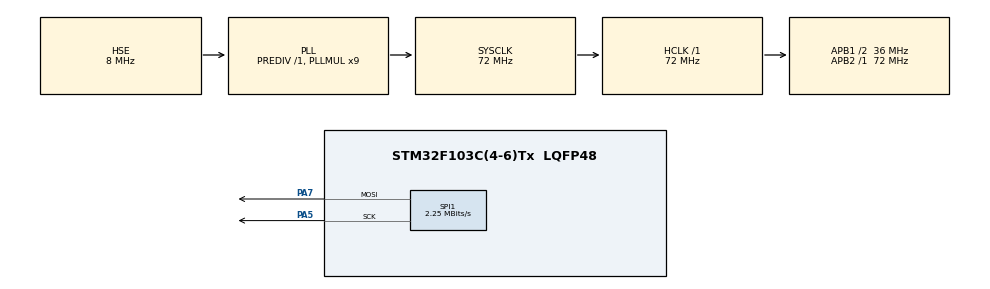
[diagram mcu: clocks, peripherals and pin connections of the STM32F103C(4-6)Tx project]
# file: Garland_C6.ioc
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ADC1.Channel-1\#ChannelRegularConversion=ADC_CHANNEL_TEMPSENSOR
ADC1.NbrOfConversionFlag=1
ADC1.Rank-1\#ChannelRegularConversion=1
ADC1.SamplingTime-1\#ChannelRegularConversion=ADC_SAMPLETIME_1CYCLE_5
ADC1.master=1
Dma.Request0=SPI1_TX
Dma.SPI1_TX.0.Direction=DMA_MEMORY_TO_PERIPH
Dma.SPI1_TX.0.Instance=DMA1_Channel3
Dma.SPI1_TX.0.MemDataAlignment=DMA_MDATAALIGN_BYTE
Dma.SPI1_TX.0.MemInc=DMA_MINC_ENABLE
Dma.SPI1_TX.0.Mode=DMA_NORMAL
Dma.SPI1_TX.0.PeriphDataAlignment=DMA_PDATAALIGN_BYTE
Dma.SPI1_TX.0.PeriphInc=DMA_PINC_DISABLE
Dma.SPI1_TX.0.Priority=DMA_PRIORITY_LOW
Mcu.Family=STM32F1
Mcu.Name=STM32F103C(4-6)Tx
Mcu.Package=LQFP48
NVIC.ADC1_2_IRQn=true\:0\:0\:false\:false\:true\:true\:true\:true
NVIC.DMA1_Channel3_IRQn=true\:0\:0\:false\:false\:true\:false\:true\:true
NVIC.PriorityGroup=NVIC_PRIORITYGROUP_4
NVIC.TIM1_BRK_IRQn=true\:0\:0\:false\:false\:true\:true\:true\:true
NVIC.TIM1_CC_IRQn=true\:0\:0\:false\:false\:true\:true\:true\:true
NVIC.TIM1_TRG_COM_IRQn=true\:0\:0\:false\:false\:true\:true\:true\:true
NVIC.TIM1_UP_IRQn=true\:0\:0\:false\:false\:true\:true\:true\:true
PA13.Mode=Serial_Wire
PA13.Signal=SYS_JTMS-SWDIO
PA14.Mode=Serial_Wire
PA14.Signal=SYS_JTCK-SWCLK
PA5.Mode=TX_Only_Simplex_Unidirect_Master
PA5.Signal=SPI1_SCK
PA7.Mode=TX_Only_Simplex_Unidirect_Master
PA7.Signal=SPI1_MOSI
PD0-OSC_IN.Mode=HSE-External-Oscillator
PD0-OSC_IN.Signal=RCC_OSC_IN
PD1-OSC_OUT.Mode=HSE-External-Oscillator
PD1-OSC_OUT.Signal=RCC_OSC_OUT
ProjectManager.HeapSize=0x0
ProjectManager.StackSize=0x400
ProjectManager.TargetToolchain=STM32CubeIDE
RCC.ADCPresc=RCC_ADCPCLK2_DIV6
RCC.AHBFreq_Value=72000000
RCC.APB1CLKDivider=RCC_HCLK_DIV2
RCC.APB1Freq_Value=36000000
RCC.APB1TimFreq_Value=72000000
RCC.APB2Freq_Value=72000000
RCC.APB2TimFreq_Value=72000000
RCC.FLatency=FLASH_LATENCY_2
RCC.HCLKFreq_Value=72000000
RCC.PLLMUL=RCC_PLL_MUL9
RCC.PLLSourceVirtual=RCC_PLLSOURCE_HSE
RCC.SYSCLKFreq_VALUE=72000000
RCC.SYSCLKSource=RCC_SYSCLKSOURCE_PLLCLK
RCC.USBFreq_Value=72000000
SPI1.BaudRatePrescaler=SPI_BAUDRATEPRESCALER_32
SPI1.CLKPhase=SPI_PHASE_2EDGE
SPI1.CLKPolarity=SPI_POLARITY_LOW
SPI1.CRCCalculation=SPI_CRCCALCULATION_DISABLE
SPI1.CalculateBaudRate=2.25 MBits/s
SPI1.DataSize=SPI_DATASIZE_8BIT
SPI1.Direction=SPI_DIRECTION_2LINES
SPI1.FirstBit=SPI_FIRSTBIT_MSB
SPI1.Mode=SPI_MODE_MASTER
SPI1.NSS=SPI_NSS_SOFT
SPI1.TIMode=SPI_TIMODE_DISABLE
SPI1.VirtualType=VM_MASTER
TIM1.AutoReloadPreload=TIM_AUTORELOAD_PRELOAD_DISABLE
TIM1.ClockDivision=TIM_CLOCKDIVISION_DIV1
TIM1.CounterMode=TIM_COUNTERMODE_UP
TIM1.Period=20000
TIM1.Prescaler=71
TIM1.TIM_MasterOutputTrigger=TIM_TRGO_RESET
TIM1.TIM_MasterSlaveMode=TIM_MASTERSLAVEMODE_DISABLE
VP_ADC1_TempSens_Input.Mode=IN-TempSens
VP_CRC_VS_CRC.Mode=CRC_Activate
VP_TIM1_VS_ClockSourceINT.Mode=Internal
board=custom

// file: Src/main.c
/* USER CODE BEGIN Header */
/**
  ******************************************************************************
  * @file           : main.c
  * @brief          : Main program body
  ******************************************************************************
  * @attention
  *
  * Copyright (c) 2024 STMicroelectronics.
  * All rights reserved.
  *
  * This software is licensed under terms that can be found in the LICENSE file
  * in the root directory of this software component.
  * If no LICENSE file comes with this software, it is provided AS-IS.
  *
  ******************************************************************************
  */
/* USER CODE END Header */
#include "main.h"

/* USER CODE BEGIN Includes */
#include "random.h"
#include "ws2812.h"
#include "stdlib.h"
#include <string.h>
/* USER CODE END Includes */

/* USER CODE BEGIN PD */
#define TIMER_PERIOD_MS			20	// Период вызова функции обновления состояния
#define TIME_MIN_TICK			(TIME_MIN_MSEC / TIMER_PERIOD_MS)
#define TIME_MAX_TICK			(TIME_MAX_MSEC / TIMER_PERIOD_MS)
/* USER CODE END PD */

ADC_HandleTypeDef hadc1;

CRC_HandleTypeDef hcrc;

SPI_HandleTypeDef hspi1;
DMA_HandleTypeDef hdma_spi1_tx;

TIM_HandleTypeDef htim1;

/* USER CODE BEGIN PV */
volatile uint8_t timFlag = 0;
volatile uint8_t dmaFlag = 1;
uint32_t rgbArr[LED_NUM]; // кольцевой массив
const uint32_t rgbConst[8]={0x000000, 0x00007F, 0x007F00, 0x007F7F, 0x7F0000, 0x7F007F, 0x7F7F00, 0x7F7F7F};
volatile uint32_t timerCounter;
/* USER CODE END PV */

void SystemClock_Config(void);
static void MX_GPIO_Init(void);
static void MX_DMA_Init(void);
static void MX_SPI1_Init(void);
static void MX_ADC1_Init(void);
static void MX_CRC_Init(void);
static void MX_TIM1_Init(void);

/* USER CODE BEGIN 0 */
void HAL_ADC_ConvCpltCallback(ADC_HandleTypeDef* hadc)
{
	static uint32_t count = 0;
	count++;
	uint32_t adc = HAL_ADC_GetValue(hadc);
	uint8_t ans = Random_AddBit(adc);
	if (ans != 0)
		HAL_ADC_Start_IT(&hadc1);
	else
		__NOP();
}

void HAL_TIM_PeriodElapsedCallback(TIM_HandleTypeDef *htim)
{
	timFlag = 1;
	timerCounter++;
}

void HAL_SPI_TxCpltCallback(SPI_HandleTypeDef *hspi)
{
	dmaFlag = 1 ;
}

// type  0 - linear; 1 - V образный
// при 0 - возврат 32 бит, при 1 - только 8
uint32_t GetRandom(uint8_t type)
{
	uint32_t rnd;
	static uint8_t isFirst = 1;
	if (isFirst)
	{
		isFirst = 0;
		rnd = Random_GetRnd();
		HAL_ADC_Start_IT(&hadc1);
		while (!rnd)
		{
			rnd = Random_GetRnd();
		};
		srand(rnd);
	}

	rnd = rand();
	if (type == 0)
		return rnd;

	// V
	return Random_GetV(rnd);
}

// Бегущие огни
void Prog_0()
{
	static uint32_t timer = 0;
	static uint32_t curr = 0;
	static uint32_t dest = 0;

	uint8_t* currP = (uint8_t*)&curr;
	uint8_t* destP = (uint8_t*)&dest;
	// Задаем цвет нулевому диоду
	if (!timer)
	{
		timer = 0xFF;
		curr = dest;
		do
		{
			dest = rgbConst[GetRandom(0)&7];
		}while (curr == dest);

	}
	else
	{
		timer--;
		for(int i=0; i<3; i++)
			if (destP[i])
			{
				if (currP[i] < 0xFF)
					currP[i]++;
			}
			else
			{
				if (currP[i] > 0)
					currP[i]--;
			}
	}

	// Передаем в массив
	for (int i = LED_NUM-1; i>0; i--)
		rgbArr[i] = rgbArr[i-1];

	rgbArr[0] = curr;

	for(int i=0; i<LED_NUM; i++)
		ws2813_AddRGB(rgbArr[i], i);
}

// Случайная вспышка
void Prog_1()
{
	for (int i=0; i<10; i++)
	{
		uint32_t rnd = rgbConst[GetRandom(0)&7];
		uint16_t pos = GetRandom(0) % LED_NUM;
		rgbArr[pos] = rnd;
	}
	for (int i=0; i<LED_NUM; i++)
		ws2813_AddRGB(rgbArr[i], i);
}

// Бегущие огни 2
void Prog_2()
{

	static uint32_t timer = 0;
	static uint32_t curr = 0;
	static uint16_t arrPos = 0; // указатель на начало массива

	// Задаем цвет нулевому диоду
	if (!timer)
	{
		timer = 25;//(TIME_MIN_TICK + GetRandom(0)) % TIME_MAX_TICK;
		curr = rgbConst[GetRandom(0)&7];

	}
	else
	{
		timer--;
	}

	rgbArr[arrPos] = curr;

	// Передаем в массив
	int pos = LED_NUM - 1;
	for (int i=arrPos; i<LED_NUM; i++)
		ws2813_AddRGB(rgbArr[i], pos--);
	for(int i=0; i<arrPos; i++)
		ws2813_AddRGB(rgbArr[i], pos--);

	arrPos++;
	if (arrPos == LED_NUM)
		arrPos = 0;

}

// Бегущие огни
void Prog_3()
{
	#define MAX_NUM 16
	static int16_t pos[MAX_NUM];
	static uint32_t rgb[MAX_NUM];

	static uint8_t isFirst = 1;
	static int delay = 0;
	if (isFirst)
	{
		isFirst = 0;
		for (int i=0; i<MAX_NUM; i++)
		{
			pos[i] = LED_NUM * i / MAX_NUM;
			rgb[i] = rgbConst[GetRandom(0)&7];
		}
	}

	if ((delay++ & 0x1F) == 0)
	{
		for (int i=0; i<MAX_NUM; i++)
			if (++pos[i]==LED_NUM)
			{
				rgb[i] = rgbConst[GetRandom(0)&7];
				pos[i] = 0;
			}

		// Передаем в массив
		memset(rgbArr, 0, LED_NUM*4);
		for (int i=0; i<MAX_NUM; i++)
			rgbArr[pos[i]] = rgb[i];
	}
	for(int i=0; i<LED_NUM; i++)
		ws2813_AddRGB(rgbArr[i], i);

}

void Prog_4()
{
	#define DIVIDER (50*5) // 5сек
	static uint32_t tim = 0;
	if (!tim)
	{
		tim = DIVIDER;
		for( int i=0; i<LED_NUM; i++)
			rgbArr[i] = rgbConst[GetRandom(0)&7];
	}
	tim--;

	for(int i=0; i<LED_NUM; i++)
		ws2813_AddRGB(rgbArr[i], i);
}
/* USER CODE END 0 */

int main(void)
{

  /* MCU Configuration--------------------------------------------------------*/

  /* Reset of all peripherals, Initializes the Flash interface and the Systick. */
  HAL_Init();

  /* Configure the system clock */
  SystemClock_Config();

  /* Initialize all configured peripherals */
  MX_GPIO_Init();
  MX_DMA_Init();
  MX_SPI1_Init();
  MX_ADC1_Init();
  MX_CRC_Init();
  MX_TIM1_Init();
  /* USER CODE BEGIN 2 */
  HAL_TIM_Base_Start_IT(&htim1);
  //HAL_TIM_Base_Start_IT(&htim1);
  HAL_ADC_Start_IT(&hadc1);
  ws2813_FillConvertBuffer();
//  HAL_TIM_Base_Start_IT(&htim1);
  /* USER CODE END 2 */

  /* Infinite loop */
  /* USER CODE BEGIN WHILE */
  static uint8_t currentProg = 3;
  while (1)
  {
		if (timerCounter == 50*60*3) // 3 минуты
			{
				timerCounter = 0;
				currentProg++;
			}

			switch(currentProg)
			{
				case 0:
					Prog_0();
					break;
				case 1:
					Prog_1();
					break;
				case 2:
					Prog_2();
					break;
				case 3:
					Prog_3();
					break;
				case 4:
					Prog_4();
					break;
				default:
					currentProg = 0;
					break;
			}

			while(!dmaFlag);
			dmaFlag = 0;

			while(!timFlag);
			timFlag = 0;

			uint8_t *cdmaBuff = ws2813_GetDMAbuff();
			HAL_SPI_Transmit_DMA(&hspi1, cdmaBuff, DMA_BUFF_SIZE);
			ws2813_ChangeCurrentBuff();
    /* USER CODE END WHILE */

  }
}

void SystemClock_Config(void)
{
  RCC_OscInitTypeDef RCC_OscInitStruct = {0};
  RCC_ClkInitTypeDef RCC_ClkInitStruct = {0};
  RCC_PeriphCLKInitTypeDef PeriphClkInit = {0};

  /** Initializes the RCC Oscillators according to the specified parameters
  * in the RCC_OscInitTypeDef structure.
  */
  RCC_OscInitStruct.OscillatorType = RCC_OSCILLATORTYPE_HSE;
  RCC_OscInitStruct.HSEState = RCC_HSE_ON;
  RCC_OscInitStruct.HSEPredivValue = RCC_HSE_PREDIV_DIV1;
  RCC_OscInitStruct.HSIState = RCC_HSI_ON;
  RCC_OscInitStruct.PLL.PLLState = RCC_PLL_ON;
  RCC_OscInitStruct.PLL.PLLSource = RCC_PLLSOURCE_HSE;
  RCC_OscInitStruct.PLL.PLLMUL = RCC_PLL_MUL9;
  if (HAL_RCC_OscConfig(&RCC_OscInitStruct) != HAL_OK)
  {
    Error_Handler();
  }

  /** Initializes the CPU, AHB and APB buses clocks
  */
  RCC_ClkInitStruct.ClockType = RCC_CLOCKTYPE_HCLK|RCC_CLOCKTYPE_SYSCLK
                              |RCC_CLOCKTYPE_PCLK1|RCC_CLOCKTYPE_PCLK2;
  RCC_ClkInitStruct.SYSCLKSource = RCC_SYSCLKSOURCE_PLLCLK;
  RCC_ClkInitStruct.AHBCLKDivider = RCC_SYSCLK_DIV1;
  RCC_ClkInitStruct.APB1CLKDivider = RCC_HCLK_DIV2;
  RCC_ClkInitStruct.APB2CLKDivider = RCC_HCLK_DIV1;

  if (HAL_RCC_ClockConfig(&RCC_ClkInitStruct, FLASH_LATENCY_2) != HAL_OK)
  {
    Error_Handler();
  }
  PeriphClkInit.PeriphClockSelection = RCC_PERIPHCLK_ADC;
  PeriphClkInit.AdcClockSelection = RCC_ADCPCLK2_DIV6;
  if (HAL_RCCEx_PeriphCLKConfig(&PeriphClkInit) != HAL_OK)
  {
    Error_Handler();
  }
}

static void MX_ADC1_Init(void)
{

  ADC_ChannelConfTypeDef sConfig = {0};

  /** Common config
  */
  hadc1.Instance = ADC1;
  hadc1.Init.ScanConvMode = ADC_SCAN_DISABLE;
  hadc1.Init.ContinuousConvMode = DISABLE;
  hadc1.Init.DiscontinuousConvMode = DISABLE;
  hadc1.Init.ExternalTrigConv = ADC_SOFTWARE_START;
  hadc1.Init.DataAlign = ADC_DATAALIGN_RIGHT;
  hadc1.Init.NbrOfConversion = 1;
  if (HAL_ADC_Init(&hadc1) != HAL_OK)
  {
    Error_Handler();
  }

  /** Configure Regular Channel
  */
  sConfig.Channel = ADC_CHANNEL_TEMPSENSOR;
  sConfig.Rank = ADC_REGULAR_RANK_1;
  sConfig.SamplingTime = ADC_SAMPLETIME_1CYCLE_5;
  if (HAL_ADC_ConfigChannel(&hadc1, &sConfig) != HAL_OK)
  {
    Error_Handler();
  }

}

static void MX_CRC_Init(void)
{

  hcrc.Instance = CRC;
  if (HAL_CRC_Init(&hcrc) != HAL_OK)
  {
    Error_Handler();
  }

}

static void MX_SPI1_Init(void)
{

  /* SPI1 parameter configuration*/
  hspi1.Instance = SPI1;
  hspi1.Init.Mode = SPI_MODE_MASTER;
  hspi1.Init.Direction = SPI_DIRECTION_2LINES;
  hspi1.Init.DataSize = SPI_DATASIZE_8BIT;
  hspi1.Init.CLKPolarity = SPI_POLARITY_LOW;
  hspi1.Init.CLKPhase = SPI_PHASE_2EDGE;
  hspi1.Init.NSS = SPI_NSS_SOFT;
  hspi1.Init.BaudRatePrescaler = SPI_BAUDRATEPRESCALER_32;
  hspi1.Init.FirstBit = SPI_FIRSTBIT_MSB;
  hspi1.Init.TIMode = SPI_TIMODE_DISABLE;
  hspi1.Init.CRCCalculation = SPI_CRCCALCULATION_DISABLE;
  hspi1.Init.CRCPolynomial = 10;
  if (HAL_SPI_Init(&hspi1) != HAL_OK)
  {
    Error_Handler();
  }

}

static void MX_TIM1_Init(void)
{

  TIM_ClockConfigTypeDef sClockSourceConfig = {0};
  TIM_MasterConfigTypeDef sMasterConfig = {0};

  htim1.Instance = TIM1;
  htim1.Init.Prescaler = 71;
  htim1.Init.CounterMode = TIM_COUNTERMODE_UP;
  htim1.Init.Period = 20000;
  htim1.Init.ClockDivision = TIM_CLOCKDIVISION_DIV1;
  htim1.Init.RepetitionCounter = 0;
  htim1.Init.AutoReloadPreload = TIM_AUTORELOAD_PRELOAD_DISABLE;
  if (HAL_TIM_Base_Init(&htim1) != HAL_OK)
  {
    Error_Handler();
  }
  sClockSourceConfig.ClockSource = TIM_CLOCKSOURCE_INTERNAL;
  if (HAL_TIM_ConfigClockSource(&htim1, &sClockSourceConfig) != HAL_OK)
  {
    Error_Handler();
  }
  sMasterConfig.MasterOutputTrigger = TIM_TRGO_RESET;
  sMasterConfig.MasterSlaveMode = TIM_MASTERSLAVEMODE_DISABLE;
  if (HAL_TIMEx_MasterConfigSynchronization(&htim1, &sMasterConfig) != HAL_OK)
  {
    Error_Handler();
  }

}

static void MX_DMA_Init(void)
{

  /* DMA controller clock enable */
  __HAL_RCC_DMA1_CLK_ENABLE();

  /* DMA interrupt init */
  /* DMA1_Channel3_IRQn interrupt configuration */
  HAL_NVIC_SetPriority(DMA1_Channel3_IRQn, 0, 0);
  HAL_NVIC_EnableIRQ(DMA1_Channel3_IRQn);

}

static void MX_GPIO_Init(void)
{

  /* GPIO Ports Clock Enable */
  __HAL_RCC_GPIOD_CLK_ENABLE();
  __HAL_RCC_GPIOA_CLK_ENABLE();

}

void Error_Handler(void)
{
  __disable_irq();
  while (1)
  {
  }
}
